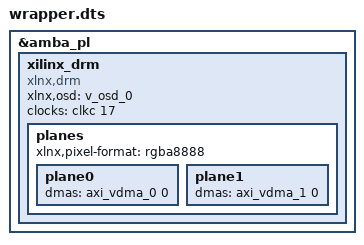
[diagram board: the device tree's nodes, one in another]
/**
 * CAUTION: This file is automatically generated by Xilinx.
 * Version: HSI 2016.3
 * Today is: Thu Nov 24 17:48:26 2016
 */
/include/ "system.dts"
&amba_pl {
	xilinx_drm {
		compatible = "xlnx,drm";
		//status = "disabled";
		xlnx,osd = <&v_osd_0>;
		//xlnx,vtc = <&v_tc_0>;
		clocks = <&clkc 17>;

		planes {
			xlnx,pixel-format = "rgba8888";
			plane0 {
				dmas = <&axi_vdma_0 0>;
				dma-names = "dma0";
			};
			plane1 {
				dmas = <&axi_vdma_1 0>;
				dma-names = "dma1";
			};
		};
	};
};
